VERSION ""

NS_ :

BS_:

BU_: XXX

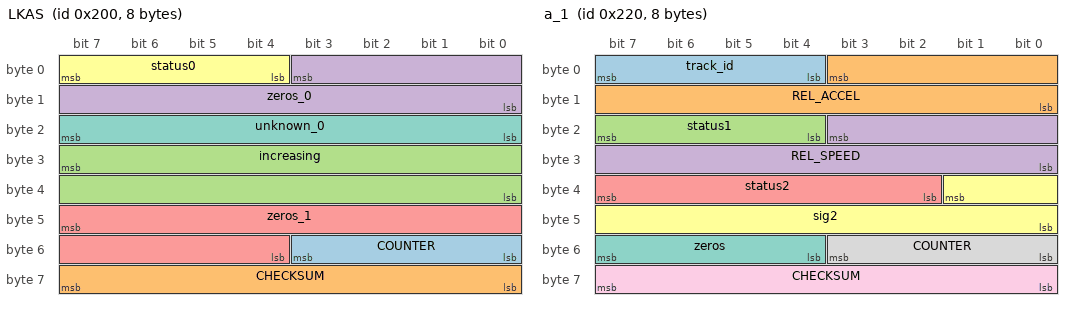
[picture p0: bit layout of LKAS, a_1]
BO_ 512 LKAS: 8 XXX
 SG_ COUNTER : 51|4@0+ (1,0) [0|15] "" XXX
 SG_ CHECKSUM : 63|8@0+ (1,0) [0|255] "" XXX
 SG_ increasing : 31|16@0+ (1,0) [0|255] "" XXX
 SG_ zeros_0 : 3|12@0+ (1,0) [0|63] "" XXX
 SG_ zeros_1 : 47|12@0+ (1,0) [0|63] "" XXX
 SG_ status0 : 7|4@0+ (1,0) [0|15] "" XXX
 SG_ unknown_0 : 23|8@0+ (1,0) [0|255] "" XXX

BO_ 544 a_1: 8 XXX
 SG_ track_id : 7|4@0+ (1,0) [0|15] "" XXX
 SG_ REL_ACCEL : 3|12@0+ (1,0) [0|31] "" XXX
 SG_ status1 : 23|4@0+ (1,0) [0|15] "" XXX
 SG_ REL_SPEED : 19|12@0+ (1,0) [0|65535] "" XXX
 SG_ status2 : 39|6@0+ (1,0) [0|15] "" XXX
 SG_ sig2 : 33|10@0+ (1,0) [0|255] "" XXX
 SG_ zeros : 55|4@0+ (1,0) [0|15] "" XXX
 SG_ COUNTER : 51|4@0+ (1,0) [0|15] "" XXX
 SG_ CHECKSUM : 63|8@0+ (1,0) [0|255] "" XXX

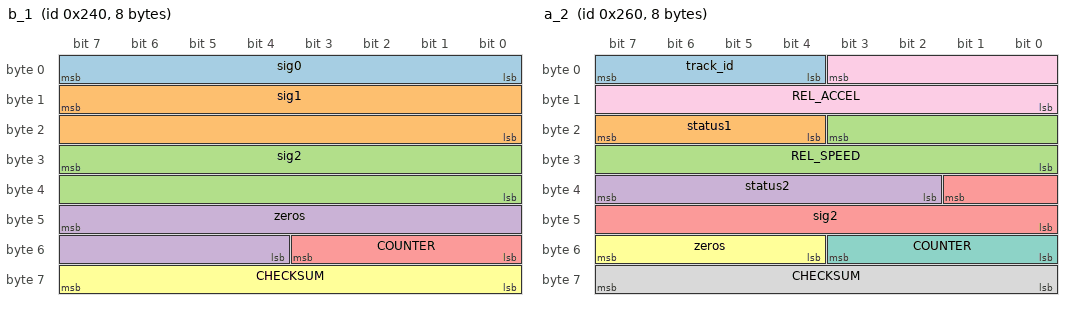
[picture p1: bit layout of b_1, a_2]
BO_ 576 b_1: 8 XXX
 SG_ sig0 : 7|8@0+ (1,0) [0|255] "" XXX
 SG_ sig1 : 15|16@0+ (1,0) [0|65535] "" XXX
 SG_ sig2 : 31|16@0+ (1,0) [0|255] "" XXX
 SG_ zeros : 47|12@0+ (1,0) [0|255] "" XXX
 SG_ COUNTER : 51|4@0+ (1,0) [0|15] "" XXX
 SG_ CHECKSUM : 63|8@0+ (1,0) [0|255] "" XXX

BO_ 608 a_2: 8 XXX
 SG_ track_id : 7|4@0+ (1,0) [0|15] "" XXX
 SG_ status1 : 23|4@0+ (1,0) [0|15] "" XXX
 SG_ REL_SPEED : 19|12@0+ (1,0) [0|65535] "" XXX
 SG_ status2 : 39|6@0+ (1,0) [0|15] "" XXX
 SG_ sig2 : 33|10@0+ (1,0) [0|255] "" XXX
 SG_ zeros : 55|4@0+ (1,0) [0|15] "" XXX
 SG_ COUNTER : 51|4@0+ (1,0) [0|15] "" XXX
 SG_ CHECKSUM : 63|8@0+ (1,0) [0|255] "" XXX
 SG_ REL_ACCEL : 3|12@0+ (1,0) [0|31] "" XXX

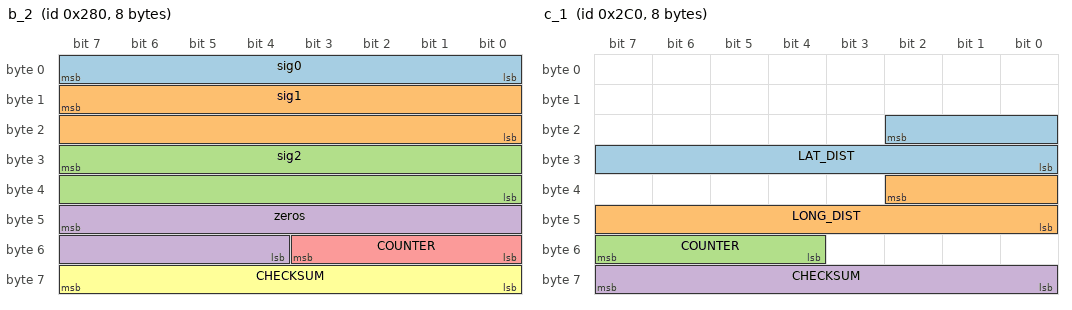
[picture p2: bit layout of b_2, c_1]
BO_ 640 b_2: 8 XXX
 SG_ sig0 : 7|8@0+ (1,0) [0|255] "" XXX
 SG_ sig1 : 15|16@0+ (1,0) [0|65535] "" XXX
 SG_ sig2 : 31|16@0+ (1,0) [0|255] "" XXX
 SG_ zeros : 47|12@0+ (1,0) [0|255] "" XXX
 SG_ COUNTER : 51|4@0+ (1,0) [0|15] "" XXX
 SG_ CHECKSUM : 63|8@0+ (1,0) [0|255] "" XXX

BO_ 704 c_1: 8 XXX
 SG_ LAT_DIST : 18|11@0+ (0.005,-7) [0|2047] "m" XXX
 SG_ LONG_DIST : 34|11@0+ (0.05,0) [0|255] "m" XXX
 SG_ COUNTER : 55|4@0+ (1,0) [0|15] "" XXX
 SG_ CHECKSUM : 63|8@0+ (1,0) [0|255] "" XXX

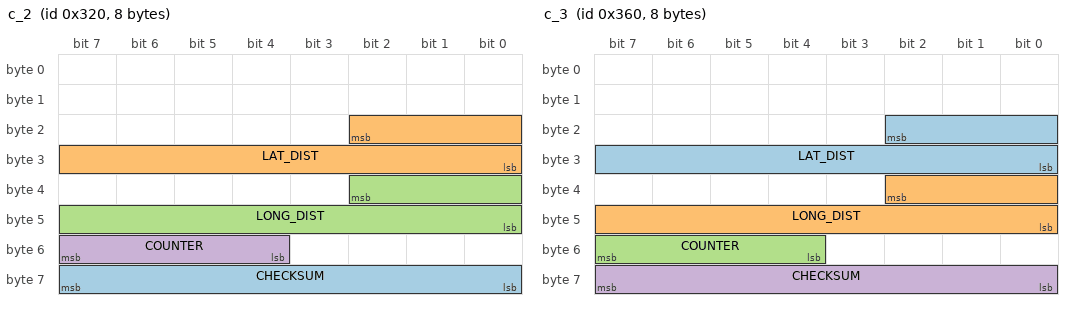
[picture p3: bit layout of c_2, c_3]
BO_ 800 c_2: 8 XXX
 SG_ CHECKSUM : 63|8@0+ (1,0) [0|255] "" XXX
 SG_ LAT_DIST : 18|11@0+ (0.005,-7) [0|2047] "m" XXX
 SG_ LONG_DIST : 34|11@0+ (0.05,0) [0|255] "m" XXX
 SG_ COUNTER : 55|4@0+ (1,0) [0|15] "" XXX

BO_ 864 c_3: 8 XXX
 SG_ LAT_DIST : 18|11@0+ (0.005,-7) [0|2047] "m" XXX
 SG_ LONG_DIST : 34|11@0+ (0.05,0) [0|255] "m" XXX
 SG_ COUNTER : 55|4@0+ (1,0) [0|15] "" XXX
 SG_ CHECKSUM : 63|8@0+ (1,0) [0|255] "" XXX

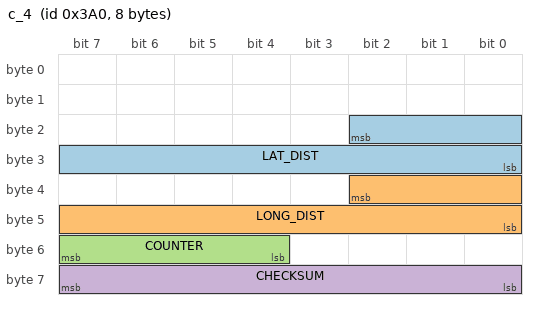
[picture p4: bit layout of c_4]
BO_ 928 c_4: 8 XXX
 SG_ LAT_DIST : 18|11@0+ (0.005,-7) [0|2047] "m" XXX
 SG_ LONG_DIST : 34|11@0+ (0.05,0) [0|255] "m" XXX
 SG_ COUNTER : 55|4@0+ (1,0) [0|15] "" XXX
 SG_ CHECKSUM : 63|8@0+ (1,0) [0|255] "" XXX

BO_ 672 d_1: 8 XXX
 SG_ TRACK_ID : 15|6@0+ (1,0) [0|1] "" XXX
 SG_ REL_SPEED : 9|10@0+ (0.2857,-146.278) [0|1023] "m/s" XXX

BO_ 768 d_2: 8 XXX
 SG_ REL_SPEED : 9|10@0+ (0.2857,-146.278) [0|1023] "m/s" XXX
 SG_ TRACK_ID : 15|6@0+ (1,0) [0|1] "" XXX

BO_ 832 d_3: 8 XXX
 SG_ REL_SPEED : 9|10@0+ (0.2857,-146.278) [0|1023] "m/s" XXX
 SG_ TRACK_ID : 15|6@0+ (1,0) [0|1] "" XXX

BO_ 896 d_4: 8 XXX
 SG_ REL_SPEED : 9|10@0+ (0.2857,-146.278) [0|1023] "m/s" XXX
 SG_ TRACK_ID : 15|6@0+ (1,0) [0|1] "" XXX

CM_ SG_ 544 track_id "for message a_1 track_id is always 1, similar for other messages and track_id";
CM_ SG_ 544 REL_ACCEL "perhaps REL_ACCEL because it responds faster and before REL_SPEED";
CM_ SG_ 544 sig2 "perhaps distance to object. LONG_DIST or REL_ACCEL or REL_SPEED";
CM_ SG_ 576 zeros "not always zero, sometimes has value when another car changes lanes";
CM_ SG_ 704 LAT_DIST "positive to the right, negative to the left";
CM_ SG_ 800 LAT_DIST "positive to the right, negative to the left";
CM_ SG_ 864 LAT_DIST "positive to the right, negative to the left";
CM_ SG_ 928 LAT_DIST "positive to the right, negative to the left";
CM_ SG_ 672 REL_SPEED "baseline 0x200";
